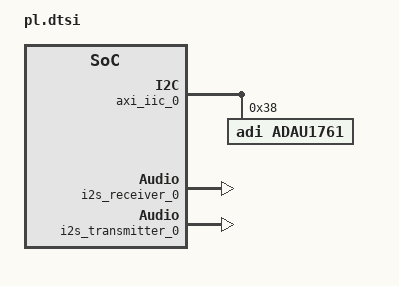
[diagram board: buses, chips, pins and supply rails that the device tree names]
/*
 * CAUTION: This file is automatically generated by Xilinx.
 * Version: XSCT 2024.2
 * Today is: Tue Nov  4 13:41:07 2025
 */


/ {
	amba_pl: pl-bus {
		#address-cells = <1>;
		#size-cells = <1>;
		compatible = "simple-bus";
		ranges ;
		audio_formatter_0: audio_formatter@43c00000 {
			clock-names = "aud_mclk", "m_axis_mm2s_aclk", "s_axi_lite_aclk", "s_axis_s2mm_aclk";
			clocks = <&misc_clk_0>, <&misc_clk_1>, <&misc_clk_1>, <&misc_clk_1>;
			compatible = "xlnx,audio-formatter-1.0", "xlnx,audio-formatter-1.0";
			interrupt-names = "irq_mm2s", "irq_s2mm";
			interrupt-parent = <&intc>;
			interrupts = <0 30 4 0 32 4>;
			reg = <0x43c00000 0x10000>;
			xlnx,include-mm2s = <0x1>;
			xlnx,include-s2mm = <0x1>;
			xlnx,max-num-channels-mm2s = <0x2>;
			xlnx,max-num-channels-s2mm = <0x2>;
			xlnx,mm2s-addr-width = <0x40>;
			xlnx,mm2s-async-clock = <0x1>;
			xlnx,mm2s-dataformat = <0x3>;
			xlnx,packing-mode-mm2s = <0x0>;
			xlnx,packing-mode-s2mm = <0x0>;
			xlnx,rx = <&i2s_receiver_0>;
			xlnx,s2mm-addr-width = <0x40>;
			xlnx,s2mm-async-clock = <0x1>;
			xlnx,s2mm-dataformat = <0x1>;
			xlnx,tx = <&i2s_transmitter_0>;
		};
		axi_iic_0: i2c@41600000 {
			#address-cells = <1>;
			#size-cells = <0>;
			clock-names = "s_axi_aclk";
			clocks = <&misc_clk_1>;
			compatible = "xlnx,axi-iic-2.1", "xlnx,xps-iic-2.00.a";
			interrupt-names = "iic2intc_irpt";
			interrupt-parent = <&intc>;
			interrupts = <0 33 4>;
			reg = <0x41600000 0x10000>;
			adau1761: adau1761@38 {
				#sound-dai-cells = <0>;
				compatible = "adi,adau1761";
				clock-names = "mclk";
				clocks = <&misc_clk_1>;
				reg = <0x38>;
			};
		};
		i2s_receiver_0: i2s_receiver@43c10000 {
			aud_mclk = <24000000>;
			clock-names = "aud_mclk", "m_axis_aud_aclk", "s_axi_ctrl_aclk";
			clocks = <&misc_clk_0>, <&misc_clk_1>, <&misc_clk_1>;
			compatible = "xlnx,i2s-receiver-1.0", "xlnx,i2s-receiver-1.0";
			interrupt-names = "irq";
			interrupt-parent = <&intc>;
			interrupts = <0 31 4>;
			reg = <0x43c10000 0x10000>;
			xlnx,depth = <0x80>;
			xlnx,dwidth = <0x18>;
			xlnx,num-channels = <0x1>;
			xlnx,snd-pcm = <&audio_formatter_0>;
		};
		i2s_transmitter_0: i2s_transmitter@43c20000 {
			aud_mclk = <24000000>;
			clock-names = "aud_mclk", "s_axi_ctrl_aclk", "s_axis_aud_aclk";
			clocks = <&misc_clk_0>, <&misc_clk_1>, <&misc_clk_1>;
			compatible = "xlnx,i2s-transmitter-1.0", "xlnx,i2s-transmitter-1.0";
			interrupt-names = "irq";
			interrupt-parent = <&intc>;
			interrupts = <0 29 4>;
			reg = <0x43c20000 0x10000>;
			xlnx,depth = <0x80>;
			xlnx,dwidth = <0x18>;
			xlnx,num-channels = <0x1>;
			xlnx,snd-pcm = <&audio_formatter_0>;
		};
	};
	misc_clk_0: misc_clk_0 {
		#clock-cells = <0>;
		clock-frequency = <24000000>;
		compatible = "fixed-clock";
	};
	misc_clk_1: misc_clk_1 {
		#clock-cells = <0>;
		clock-frequency = <48000000>;
		compatible = "fixed-clock";
	};
};
